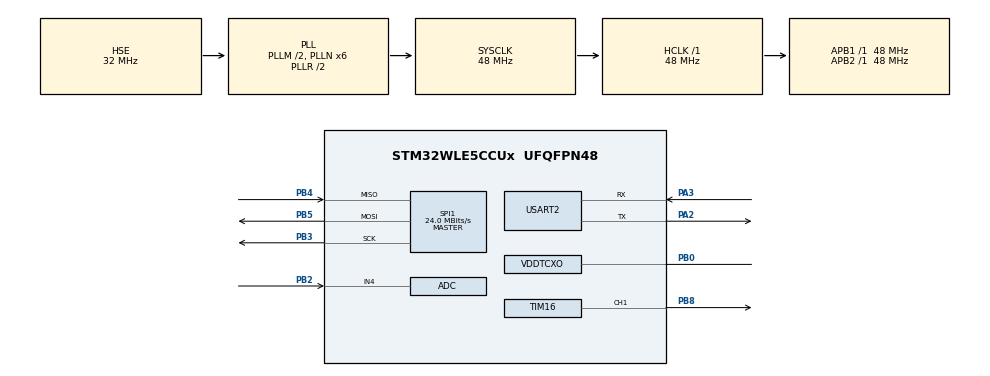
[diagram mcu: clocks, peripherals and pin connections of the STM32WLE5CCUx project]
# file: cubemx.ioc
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ADC.Channel-0\#ChannelRegularConversion=ADC_CHANNEL_4
ADC.ContinuousConvMode=DISABLE
ADC.DMAContinuousRequests=ENABLE
ADC.EOCSelection=ADC_EOC_SINGLE_CONV
ADC.EnableRegularConversion=ENABLE
ADC.NbrOfConversion=1
ADC.NbrOfConversionFlag=1
ADC.Rank-0\#ChannelRegularConversion=1
ADC.SamplingTime-0\#ChannelRegularConversion=ADC_SAMPLINGTIME_COMMON_1
ADC.SamplingTimeCommon1=ADC_SAMPLETIME_39CYCLES_5
ADC.SamplingTimeCommon2=ADC_SAMPLETIME_39CYCLES_5
ADC.SelectedChannel=ADC_CHANNEL_4
Dma.ADC.0.Direction=DMA_PERIPH_TO_MEMORY
Dma.ADC.0.EventEnable=DISABLE
Dma.ADC.0.Instance=DMA1_Channel1
Dma.ADC.0.MemDataAlignment=DMA_MDATAALIGN_WORD
Dma.ADC.0.MemInc=DMA_MINC_ENABLE
Dma.ADC.0.Mode=DMA_CIRCULAR
Dma.ADC.0.PeriphDataAlignment=DMA_PDATAALIGN_WORD
Dma.ADC.0.PeriphInc=DMA_PINC_DISABLE
Dma.ADC.0.Polarity=HAL_DMAMUX_REQ_GEN_RISING
Dma.ADC.0.Priority=DMA_PRIORITY_HIGH
Dma.ADC.0.RequestNumber=1
Dma.ADC.0.SignalID=NONE
Dma.ADC.0.SyncEnable=DISABLE
Dma.ADC.0.SyncPolarity=HAL_DMAMUX_SYNC_NO_EVENT
Dma.ADC.0.SyncRequestNumber=1
Dma.ADC.0.SyncSignalID=NONE
Dma.Request0=ADC
Dma.Request1=TIM16_CH1
Dma.TIM16_CH1.1.Direction=DMA_MEMORY_TO_PERIPH
Dma.TIM16_CH1.1.EventEnable=DISABLE
Dma.TIM16_CH1.1.Instance=DMA1_Channel2
Dma.TIM16_CH1.1.MemDataAlignment=DMA_MDATAALIGN_WORD
Dma.TIM16_CH1.1.MemInc=DMA_MINC_ENABLE
Dma.TIM16_CH1.1.Mode=DMA_NORMAL
Dma.TIM16_CH1.1.PeriphDataAlignment=DMA_PDATAALIGN_WORD
Dma.TIM16_CH1.1.PeriphInc=DMA_PINC_DISABLE
Dma.TIM16_CH1.1.Polarity=HAL_DMAMUX_REQ_GEN_RISING
Dma.TIM16_CH1.1.Priority=DMA_PRIORITY_HIGH
Dma.TIM16_CH1.1.RequestNumber=1
Dma.TIM16_CH1.1.SignalID=NONE
Dma.TIM16_CH1.1.SyncEnable=DISABLE
Dma.TIM16_CH1.1.SyncPolarity=HAL_DMAMUX_SYNC_NO_EVENT
Dma.TIM16_CH1.1.SyncRequestNumber=1
Dma.TIM16_CH1.1.SyncSignalID=NONE
Mcu.Family=STM32WL
Mcu.Name=STM32WLE5CCUx
Mcu.Package=UFQFPN48
NVIC.ADC_IRQn=true\:0\:0\:false\:false\:true\:true\:true\:true
NVIC.DMA1_Channel1_IRQn=true\:0\:0\:false\:false\:true\:false\:true\:true
NVIC.DMA1_Channel2_IRQn=true\:0\:0\:false\:false\:true\:false\:true\:true
NVIC.PriorityGroup=NVIC_PRIORITYGROUP_4
NVIC.RTC_Alarm_IRQn=true\:0\:0\:false\:false\:true\:true\:true\:true
NVIC.SUBGHZ_Radio_IRQn=true\:0\:0\:false\:false\:true\:true\:true\:true
NVIC.TIM16_IRQn=true\:0\:0\:false\:false\:true\:true\:true\:true
OSC_IN.Mode=HSE-TCXO
OSC_IN.Signal=RCC_OSC_IN
PA2.Mode=Asynchronous
PA2.Signal=USART2_TX
PA3.Mode=Asynchronous
PA3.Signal=USART2_RX
PB0-VDD_TCXO.Mode=HSE-TCXO
PB0-VDD_TCXO.Signal=VDDTCXO
PB2.Mode=IN4
PB2.Signal=ADC_IN4
PB3.Mode=Full_Duplex_Master
PB3.Signal=SPI1_SCK
PB4.Mode=Full_Duplex_Master
PB4.Signal=SPI1_MISO
PB5.Mode=Full_Duplex_Master
PB5.Signal=SPI1_MOSI
PB8.Signal=S_TIM16_CH1
PC14-OSC32_IN.Mode=LSE-External-Oscillator
PC14-OSC32_IN.Signal=RCC_OSC32_IN
PC15-OSC32_OUT.Mode=LSE-External-Oscillator
PC15-OSC32_OUT.Signal=RCC_OSC32_OUT
ProjectManager.HeapSize=0x200
ProjectManager.StackSize=0x400
ProjectManager.TargetToolchain=EWARM V9.20
RCC.AHBFreq_Value=48000000
RCC.APB1Freq_Value=48000000
RCC.APB1TimFreq_Value=48000000
RCC.APB2Freq_Value=48000000
RCC.APB2TimFreq_Value=48000000
RCC.APB3Freq_Value=48000000
RCC.CortexFreq_Value=48000000
RCC.HCLKFreq_Value=48000000
RCC.HSE_VALUE=32000000
RCC.HSI_VALUE=16000000
RCC.LSE_VALUE=32768
RCC.MSIClockRange=RCC_MSIRANGE_11
RCC.PLLM=RCC_PLLM_DIV2
RCC.PLLN=6
RCC.PLLSourceVirtual=RCC_PLLSOURCE_HSE
RCC.RTCClockSelection=RCC_RTCCLKSOURCE_LSE
RCC.SYSCLKFreq_VALUE=48000000
RCC.SYSCLKSource=RCC_SYSCLKSOURCE_PLLCLK
RCC.VCOOutputFreq_Value=96000000
RTC.Alarm-Alarm\ A=RTC_ALARM_A
SH.S_TIM16_CH1.0=TIM16_CH1,PWM Generation1 CH1
SPI1.BaudRatePrescaler=SPI_BAUDRATEPRESCALER_2
SPI1.CalculateBaudRate=24.0 MBits/s
SPI1.Direction=SPI_DIRECTION_2LINES
SPI1.Mode=SPI_MODE_MASTER
SPI1.VirtualType=VM_MASTER
TIM16.Channel=TIM_CHANNEL_1
TIM16.Period=59
USART2.VirtualMode-Asynchronous=VM_ASYNC
VP_CRC_VS_CRC.Mode=CRC_Activate
VP_IWDG_VS_IWDG.Mode=IWDG_Activate
VP_RTC_VS_RTC_Activate.Mode=RTC_Enabled
VP_RTC_VS_RTC_Alarm_A_Intern.Mode=Alarm A
VP_RTC_VS_RTC_Calendar.Mode=RTC_Calendar
VP_SUBGHZ_VS_SUBGHZ.Mode=SUBGHZ_Activate
VP_TIM16_VS_ClockSourceINT.Mode=Enable_Timer
board=custom

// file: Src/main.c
/* USER CODE BEGIN Header */
/**
  ******************************************************************************
  * @file           : main.c
  * @brief          : Main program body
  ******************************************************************************
  * @attention
  *
  * Copyright (c) 2023 STMicroelectronics.
  * All rights reserved.
  *
  * This software is licensed under terms that can be found in the LICENSE file
  * in the root directory of this software component.
  * If no LICENSE file comes with this software, it is provided AS-IS.
  *
  ******************************************************************************
  */
/* USER CODE END Header */
#include "main.h"

ADC_HandleTypeDef hadc;
DMA_HandleTypeDef hdma_adc;

CRC_HandleTypeDef hcrc;

IWDG_HandleTypeDef hiwdg;

RTC_HandleTypeDef hrtc;

SPI_HandleTypeDef hspi1;

SUBGHZ_HandleTypeDef hsubghz;

TIM_HandleTypeDef htim16;
DMA_HandleTypeDef hdma_tim16_ch1;

UART_HandleTypeDef huart2;

void SystemClock_Config(void);
static void MX_GPIO_Init(void);
static void MX_DMA_Init(void);
static void MX_ADC_Init(void);
static void MX_SPI1_Init(void);
static void MX_USART2_UART_Init(void);
static void MX_SUBGHZ_Init(void);
static void MX_CRC_Init(void);
static void MX_RTC_Init(void);
static void MX_TIM16_Init(void);
static void MX_IWDG_Init(void);

__WEAK int main(void)
{
  /* USER CODE BEGIN 1 */
//
  /* USER CODE END 1 */

  /* MCU Configuration--------------------------------------------------------*/

  /* Reset of all peripherals, Initializes the Flash interface and the Systick. */
  HAL_Init();

  /* USER CODE BEGIN Init */
//
  /* USER CODE END Init */

  /* Configure the system clock */
  SystemClock_Config();

  /* USER CODE BEGIN SysInit */
//
  /* USER CODE END SysInit */

  /* Initialize all configured peripherals */
  MX_GPIO_Init();
  MX_DMA_Init();
  MX_ADC_Init();
  MX_SPI1_Init();
  MX_USART2_UART_Init();
  MX_SUBGHZ_Init();
  MX_CRC_Init();
  MX_RTC_Init();
  MX_TIM16_Init();
  MX_IWDG_Init();
  /* USER CODE BEGIN 2 */
//
  /* USER CODE END 2 */

  /* Infinite loop */
  /* USER CODE BEGIN WHILE */
//  while (1)
//  {
    /* USER CODE END WHILE */

    /* USER CODE BEGIN 3 */
//  }
  /* USER CODE END 3 */
}

void SystemClock_Config(void)
{
  RCC_OscInitTypeDef RCC_OscInitStruct = {0};
  RCC_ClkInitTypeDef RCC_ClkInitStruct = {0};

  /** Configure LSE Drive Capability
  */
  HAL_PWR_EnableBkUpAccess();
  __HAL_RCC_LSEDRIVE_CONFIG(RCC_LSEDRIVE_LOW);

  /** Configure the main internal regulator output voltage
  */
  __HAL_PWR_VOLTAGESCALING_CONFIG(PWR_REGULATOR_VOLTAGE_SCALE1);

  /** Initializes the CPU, AHB and APB buses clocks
  */
  RCC_OscInitStruct.OscillatorType = RCC_OSCILLATORTYPE_LSI|RCC_OSCILLATORTYPE_HSE
                              |RCC_OSCILLATORTYPE_LSE;
  RCC_OscInitStruct.HSEState = RCC_HSE_BYPASS_PWR;
  RCC_OscInitStruct.LSEState = RCC_LSE_ON;
  RCC_OscInitStruct.LSIDiv = RCC_LSI_DIV1;
  RCC_OscInitStruct.HSEDiv = RCC_HSE_DIV1;
  RCC_OscInitStruct.LSIState = RCC_LSI_ON;
  RCC_OscInitStruct.PLL.PLLState = RCC_PLL_ON;
  RCC_OscInitStruct.PLL.PLLSource = RCC_PLLSOURCE_HSE;
  RCC_OscInitStruct.PLL.PLLM = RCC_PLLM_DIV2;
  RCC_OscInitStruct.PLL.PLLN = 6;
  RCC_OscInitStruct.PLL.PLLP = RCC_PLLP_DIV2;
  RCC_OscInitStruct.PLL.PLLR = RCC_PLLR_DIV2;
  RCC_OscInitStruct.PLL.PLLQ = RCC_PLLQ_DIV2;
  if (HAL_RCC_OscConfig(&RCC_OscInitStruct) != HAL_OK)
  {
    Error_Handler();
  }

  /** Configure the SYSCLKSource, HCLK, PCLK1 and PCLK2 clocks dividers
  */
  RCC_ClkInitStruct.ClockType = RCC_CLOCKTYPE_HCLK3|RCC_CLOCKTYPE_HCLK
                              |RCC_CLOCKTYPE_SYSCLK|RCC_CLOCKTYPE_PCLK1
                              |RCC_CLOCKTYPE_PCLK2;
  RCC_ClkInitStruct.SYSCLKSource = RCC_SYSCLKSOURCE_PLLCLK;
  RCC_ClkInitStruct.AHBCLKDivider = RCC_SYSCLK_DIV1;
  RCC_ClkInitStruct.APB1CLKDivider = RCC_HCLK_DIV1;
  RCC_ClkInitStruct.APB2CLKDivider = RCC_HCLK_DIV1;
  RCC_ClkInitStruct.AHBCLK3Divider = RCC_SYSCLK_DIV1;

  if (HAL_RCC_ClockConfig(&RCC_ClkInitStruct, FLASH_LATENCY_2) != HAL_OK)
  {
    Error_Handler();
  }
}

static void MX_ADC_Init(void)
{

  /* USER CODE BEGIN ADC_Init 0 */
//
  /* USER CODE END ADC_Init 0 */

  ADC_ChannelConfTypeDef sConfig = {0};

  /* USER CODE BEGIN ADC_Init 1 */
//
  /* USER CODE END ADC_Init 1 */

  /** Configure the global features of the ADC (Clock, Resolution, Data Alignment and number of conversion)
  */
  hadc.Instance = ADC;
  hadc.Init.ClockPrescaler = ADC_CLOCK_SYNC_PCLK_DIV2;
  hadc.Init.Resolution = ADC_RESOLUTION_12B;
  hadc.Init.DataAlign = ADC_DATAALIGN_RIGHT;
  hadc.Init.ScanConvMode = ADC_SCAN_DISABLE;
  hadc.Init.EOCSelection = ADC_EOC_SINGLE_CONV;
  hadc.Init.LowPowerAutoWait = DISABLE;
  hadc.Init.LowPowerAutoPowerOff = DISABLE;
  hadc.Init.ContinuousConvMode = DISABLE;
  hadc.Init.NbrOfConversion = 1;
  hadc.Init.DiscontinuousConvMode = DISABLE;
  hadc.Init.ExternalTrigConv = ADC_SOFTWARE_START;
  hadc.Init.ExternalTrigConvEdge = ADC_EXTERNALTRIGCONVEDGE_NONE;
  hadc.Init.DMAContinuousRequests = ENABLE;
  hadc.Init.Overrun = ADC_OVR_DATA_PRESERVED;
  hadc.Init.SamplingTimeCommon1 = ADC_SAMPLETIME_39CYCLES_5;
  hadc.Init.SamplingTimeCommon2 = ADC_SAMPLETIME_39CYCLES_5;
  hadc.Init.OversamplingMode = DISABLE;
  hadc.Init.TriggerFrequencyMode = ADC_TRIGGER_FREQ_HIGH;
  if (HAL_ADC_Init(&hadc) != HAL_OK)
  {
    Error_Handler();
  }

  /** Configure Regular Channel
  */
  sConfig.Channel = ADC_CHANNEL_4;
  sConfig.Rank = ADC_REGULAR_RANK_1;
  sConfig.SamplingTime = ADC_SAMPLINGTIME_COMMON_1;
  if (HAL_ADC_ConfigChannel(&hadc, &sConfig) != HAL_OK)
  {
    Error_Handler();
  }
  /* USER CODE BEGIN ADC_Init 2 */
//
  /* USER CODE END ADC_Init 2 */

}

static void MX_CRC_Init(void)
{

  /* USER CODE BEGIN CRC_Init 0 */
////
  /* USER CODE END CRC_Init 0 */

  /* USER CODE BEGIN CRC_Init 1 */
////
  /* USER CODE END CRC_Init 1 */
  hcrc.Instance = CRC;
  hcrc.Init.DefaultPolynomialUse = DEFAULT_POLYNOMIAL_ENABLE;
  hcrc.Init.DefaultInitValueUse = DEFAULT_INIT_VALUE_ENABLE;
  hcrc.Init.InputDataInversionMode = CRC_INPUTDATA_INVERSION_NONE;
  hcrc.Init.OutputDataInversionMode = CRC_OUTPUTDATA_INVERSION_DISABLE;
  hcrc.InputDataFormat = CRC_INPUTDATA_FORMAT_BYTES;
  if (HAL_CRC_Init(&hcrc) != HAL_OK)
  {
    Error_Handler();
  }
  /* USER CODE BEGIN CRC_Init 2 */
////
  /* USER CODE END CRC_Init 2 */

}

static void MX_IWDG_Init(void)
{

  hiwdg.Instance = IWDG;
  hiwdg.Init.Prescaler = IWDG_PRESCALER_4;
  hiwdg.Init.Window = 4095;
  hiwdg.Init.Reload = 4095;
  if (HAL_IWDG_Init(&hiwdg) != HAL_OK)
  {
    Error_Handler();
  }

}

static void MX_RTC_Init(void)
{

  RTC_TimeTypeDef sTime = {0};
  RTC_DateTypeDef sDate = {0};
  RTC_AlarmTypeDef sAlarm = {0};

  /** Initialize RTC Only
  */
  hrtc.Instance = RTC;
  hrtc.Init.HourFormat = RTC_HOURFORMAT_24;
  hrtc.Init.AsynchPrediv = 127;
  hrtc.Init.SynchPrediv = 255;
  hrtc.Init.OutPut = RTC_OUTPUT_DISABLE;
  hrtc.Init.OutPutRemap = RTC_OUTPUT_REMAP_NONE;
  hrtc.Init.OutPutPolarity = RTC_OUTPUT_POLARITY_HIGH;
  hrtc.Init.OutPutType = RTC_OUTPUT_TYPE_OPENDRAIN;
  hrtc.Init.OutPutPullUp = RTC_OUTPUT_PULLUP_NONE;
  hrtc.Init.BinMode = RTC_BINARY_NONE;
  if (HAL_RTC_Init(&hrtc) != HAL_OK)
  {
    Error_Handler();
  }

  /** Initialize RTC and set the Time and Date
  */
  sTime.Hours = 0x0;
  sTime.Minutes = 0x0;
  sTime.Seconds = 0x0;
  sTime.DayLightSaving = RTC_DAYLIGHTSAVING_NONE;
  sTime.StoreOperation = RTC_STOREOPERATION_RESET;
  if (HAL_RTC_SetTime(&hrtc, &sTime, RTC_FORMAT_BCD) != HAL_OK)
  {
    Error_Handler();
  }
  sDate.WeekDay = RTC_WEEKDAY_MONDAY;
  sDate.Month = RTC_MONTH_JANUARY;
  sDate.Date = 0x1;
  sDate.Year = 0x0;

  if (HAL_RTC_SetDate(&hrtc, &sDate, RTC_FORMAT_BCD) != HAL_OK)
  {
    Error_Handler();
  }

  /** Enable the Alarm A
  */
  sAlarm.AlarmTime.Hours = 0x0;
  sAlarm.AlarmTime.Minutes = 0x0;
  sAlarm.AlarmTime.Seconds = 0x0;
  sAlarm.AlarmTime.SubSeconds = 0x0;
  sAlarm.AlarmTime.DayLightSaving = RTC_DAYLIGHTSAVING_NONE;
  sAlarm.AlarmTime.StoreOperation = RTC_STOREOPERATION_RESET;
  sAlarm.AlarmMask = RTC_ALARMMASK_NONE;
  sAlarm.AlarmSubSecondMask = RTC_ALARMSUBSECONDMASK_ALL;
  sAlarm.AlarmDateWeekDaySel = RTC_ALARMDATEWEEKDAYSEL_DATE;
  sAlarm.AlarmDateWeekDay = 0x1;
  sAlarm.Alarm = RTC_ALARM_A;
  if (HAL_RTC_SetAlarm_IT(&hrtc, &sAlarm, RTC_FORMAT_BCD) != HAL_OK)
  {
    Error_Handler();
  }

}

static void MX_SPI1_Init(void)
{

  /* SPI1 parameter configuration*/
  hspi1.Instance = SPI1;
  hspi1.Init.Mode = SPI_MODE_MASTER;
  hspi1.Init.Direction = SPI_DIRECTION_2LINES;
  hspi1.Init.DataSize = SPI_DATASIZE_4BIT;
  hspi1.Init.CLKPolarity = SPI_POLARITY_LOW;
  hspi1.Init.CLKPhase = SPI_PHASE_1EDGE;
  hspi1.Init.NSS = SPI_NSS_SOFT;
  hspi1.Init.BaudRatePrescaler = SPI_BAUDRATEPRESCALER_2;
  hspi1.Init.FirstBit = SPI_FIRSTBIT_MSB;
  hspi1.Init.TIMode = SPI_TIMODE_DISABLE;
  hspi1.Init.CRCCalculation = SPI_CRCCALCULATION_DISABLE;
  hspi1.Init.CRCPolynomial = 7;
  hspi1.Init.CRCLength = SPI_CRC_LENGTH_DATASIZE;
  hspi1.Init.NSSPMode = SPI_NSS_PULSE_ENABLE;
  if (HAL_SPI_Init(&hspi1) != HAL_OK)
  {
    Error_Handler();
  }

}

static void MX_SUBGHZ_Init(void)
{

  hsubghz.Init.BaudratePrescaler = SUBGHZSPI_BAUDRATEPRESCALER_8;
  if (HAL_SUBGHZ_Init(&hsubghz) != HAL_OK)
  {
    Error_Handler();
  }

}

static void MX_TIM16_Init(void)
{

  TIM_OC_InitTypeDef sConfigOC = {0};
  TIM_BreakDeadTimeConfigTypeDef sBreakDeadTimeConfig = {0};

  htim16.Instance = TIM16;
  htim16.Init.Prescaler = 0;
  htim16.Init.CounterMode = TIM_COUNTERMODE_UP;
  htim16.Init.Period = 59;
  htim16.Init.ClockDivision = TIM_CLOCKDIVISION_DIV1;
  htim16.Init.RepetitionCounter = 0;
  htim16.Init.AutoReloadPreload = TIM_AUTORELOAD_PRELOAD_DISABLE;
  if (HAL_TIM_Base_Init(&htim16) != HAL_OK)
  {
    Error_Handler();
  }
  if (HAL_TIM_PWM_Init(&htim16) != HAL_OK)
  {
    Error_Handler();
  }
  sConfigOC.OCMode = TIM_OCMODE_PWM1;
  sConfigOC.Pulse = 0;
  sConfigOC.OCPolarity = TIM_OCPOLARITY_HIGH;
  sConfigOC.OCNPolarity = TIM_OCNPOLARITY_HIGH;
  sConfigOC.OCFastMode = TIM_OCFAST_DISABLE;
  sConfigOC.OCIdleState = TIM_OCIDLESTATE_RESET;
  sConfigOC.OCNIdleState = TIM_OCNIDLESTATE_RESET;
  if (HAL_TIM_PWM_ConfigChannel(&htim16, &sConfigOC, TIM_CHANNEL_1) != HAL_OK)
  {
    Error_Handler();
  }
  sBreakDeadTimeConfig.OffStateRunMode = TIM_OSSR_DISABLE;
  sBreakDeadTimeConfig.OffStateIDLEMode = TIM_OSSI_DISABLE;
  sBreakDeadTimeConfig.LockLevel = TIM_LOCKLEVEL_OFF;
  sBreakDeadTimeConfig.DeadTime = 0;
  sBreakDeadTimeConfig.BreakState = TIM_BREAK_DISABLE;
  sBreakDeadTimeConfig.BreakPolarity = TIM_BREAKPOLARITY_HIGH;
  sBreakDeadTimeConfig.BreakFilter = 0;
  sBreakDeadTimeConfig.AutomaticOutput = TIM_AUTOMATICOUTPUT_DISABLE;
  if (HAL_TIMEx_ConfigBreakDeadTime(&htim16, &sBreakDeadTimeConfig) != HAL_OK)
  {
    Error_Handler();
  }
  HAL_TIM_MspPostInit(&htim16);

}

static void MX_USART2_UART_Init(void)
{

  huart2.Instance = USART2;
  huart2.Init.BaudRate = 115200;
  huart2.Init.WordLength = UART_WORDLENGTH_8B;
  huart2.Init.StopBits = UART_STOPBITS_1;
  huart2.Init.Parity = UART_PARITY_NONE;
  huart2.Init.Mode = UART_MODE_TX_RX;
  huart2.Init.HwFlowCtl = UART_HWCONTROL_NONE;
  huart2.Init.OverSampling = UART_OVERSAMPLING_16;
  huart2.Init.OneBitSampling = UART_ONE_BIT_SAMPLE_DISABLE;
  huart2.Init.ClockPrescaler = UART_PRESCALER_DIV1;
  huart2.AdvancedInit.AdvFeatureInit = UART_ADVFEATURE_NO_INIT;
  if (HAL_UART_Init(&huart2) != HAL_OK)
  {
    Error_Handler();
  }
  if (HAL_UARTEx_SetTxFifoThreshold(&huart2, UART_TXFIFO_THRESHOLD_1_8) != HAL_OK)
  {
    Error_Handler();
  }
  if (HAL_UARTEx_SetRxFifoThreshold(&huart2, UART_RXFIFO_THRESHOLD_1_8) != HAL_OK)
  {
    Error_Handler();
  }
  if (HAL_UARTEx_DisableFifoMode(&huart2) != HAL_OK)
  {
    Error_Handler();
  }

}

static void MX_DMA_Init(void)
{

  /* DMA controller clock enable */
  __HAL_RCC_DMAMUX1_CLK_ENABLE();
  __HAL_RCC_DMA1_CLK_ENABLE();

  /* DMA interrupt init */
  /* DMA1_Channel1_IRQn interrupt configuration */
  HAL_NVIC_SetPriority(DMA1_Channel1_IRQn, 0, 0);
  HAL_NVIC_EnableIRQ(DMA1_Channel1_IRQn);
  /* DMA1_Channel2_IRQn interrupt configuration */
  HAL_NVIC_SetPriority(DMA1_Channel2_IRQn, 0, 0);
  HAL_NVIC_EnableIRQ(DMA1_Channel2_IRQn);

}

static void MX_GPIO_Init(void)
{

  /* GPIO Ports Clock Enable */
  __HAL_RCC_GPIOB_CLK_ENABLE();
  __HAL_RCC_GPIOA_CLK_ENABLE();
  __HAL_RCC_GPIOC_CLK_ENABLE();

}

void Error_Handler(void)
{
  __disable_irq();
  while (1)
  {
  }
}
